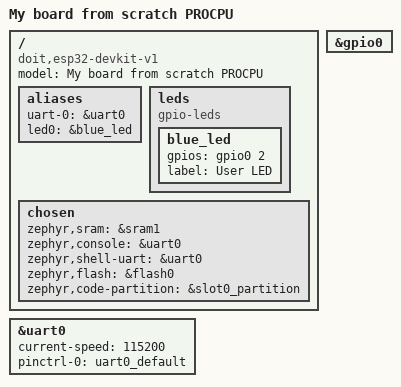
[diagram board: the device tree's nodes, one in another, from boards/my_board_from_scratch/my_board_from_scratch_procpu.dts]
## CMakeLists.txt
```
cmake_minimum_required(VERSION 3.20.0)

list (APPEND BOARD_ROOT ${CMAKE_CURRENT_SOURCE_DIR})
find_package(Zephyr REQUIRED)
project(my_zephyr_app)

target_sources(app PRIVATE src/main.cpp)
add_subdirectory(drivers/our_driver)
```

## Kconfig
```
config APP_HEARTBEAT_PERIOD_MS
	int "App Heartbeat Period (ms)"
	default 500
	range 100 2000

menuconfig LED_SUBSYSTEM
	bool "LED Subsystem"

if LED_SUBSYSTEM

# LED blink sleep time [choice]
choice
	prompt "LED blink sleep time"
	default LED_BLINK_SLEEP_1000MS

config LED_BLINK_SLEEP_250MS
	bool "0.25s (fast)"

config LED_BLINK_SLEEP_500MS
	bool "0.5s (normal)"

config LED_BLINK_SLEEP_1000MS
	bool "1s (medium)"

config LED_BLINK_SLEEP_2000MS
	bool "2s (slow)"

endchoice # LED blink sleep time

config LED_BLINK_SLEEP_TIME_MS # Use this one in the code
	int # Hidden value, no prompt
	default 250 if LED_BLINK_SLEEP_250MS	
	default 500 if LED_BLINK_SLEEP_500MS	
	default 1000 if LED_BLINK_SLEEP_1000MS	
	default 2000 if LED_BLINK_SLEEP_2000MS
	default 0


menuconfig ADVANCED_LED_SETTINGS 
	bool "Advanced LED settings"

if ADVANCED_LED_SETTINGS

config LED_BRIGHTNESS
	int "LED brightness (0-100)"
	default 100
	range 0 100

config LED_FADE_DURATION
	int "LED fade duration (ms)"
	default 500
	range 0 5000

#menu "Expert settings"
#config EXPERT_SETTINGS
#	bool "Expert settings"

# Expert settings [menu with visible if]
	# bool led debugging [config]
	# bool custom blink pattern [config]
menu "Expert settings"
visible if ADVANCED_LED_SETTINGS

config ENABLE_LED_DEBUGGING
	bool "Enable LED debugging"
	default 0

config CUSTOM_BLINK_PATTERN
	bool "Custom blink pattern"
	default 0

endmenu # Expert settings


endif # ADVANCED_LED_SETTINGS
endif # LED_SUBSYSTEM

source "Kconfig.zephyr"
rsource "drivers/our_driver/Kconfig"
```

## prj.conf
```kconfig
CONFIG_GPIO=y
CONFIG_LOG=y
CONFIG_OUR_DRIVER=y

CONFIG_SHELL=y
```

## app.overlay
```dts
/ {
	our_driver0: our_driver {
		compatible = "our,driver";
		status = "okay";
	};

	aliases {
		app-led = &blue_led;		
	};
};
```

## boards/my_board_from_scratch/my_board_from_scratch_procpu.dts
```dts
/*
 * Copyright (c) 2025 Siratul Islam
 *
 * SPDX-License-Identifier: Apache-2.0
 */
/dts-v1/;

#include <espressif/esp32/esp32_wroom_32ue_n4.dtsi>
#include "doit_esp32_devkit_v1-pinctrl.dtsi"
#include <zephyr/dt-bindings/input/input-event-codes.h>
#include <espressif/partitions_0x1000_amp.dtsi>

/ {
	model = "My board from scratch PROCPU";
	compatible = "doit,esp32-devkit-v1";

	aliases {
		uart-0 = &uart0;
		led0 = &blue_led;
	};

	leds {
		compatible = "gpio-leds";

		blue_led: blue_led {
			gpios = <&gpio0 2 GPIO_ACTIVE_HIGH>;
			label = "User LED";
		};
	};

	chosen {
		zephyr,sram = &sram1;
		zephyr,console = &uart0;
		zephyr,shell-uart = &uart0;
		zephyr,flash = &flash0;
		zephyr,code-partition = &slot0_partition;
	};
};

&uart0 {
	status = "okay";
	current-speed = <115200>;
	pinctrl-0 = <&uart0_default>;
	pinctrl-names = "default";
};


&gpio0 {
	status = "okay";
};
```

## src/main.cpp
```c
#include <zephyr/drivers/gpio.h>
#include <zephyr/kernel.h>
#include <zephyr/logging/log.h>

#include <zephyr/drivers/sensor.h> 
#include "our_driver.h" 


/* #define SLEEP_TIME_MS 1000 */

/* The devicetree node identifier for the "led0" alias. */
#define LED_NODE DT_ALIAS(led0)
#define APP_LED DT_ALIAS(app_led)

// From Module 3
//static const struct gpio_dt_spec led = GPIO_DT_SPEC_GET(LED_NODE, gpios);
// From Module 4
static const struct gpio_dt_spec led = GPIO_DT_SPEC_GET(APP_LED, gpios);

LOG_MODULE_REGISTER(main, LOG_LEVEL_INF);

namespace {
	void test(){
		const struct device* driver = DEVICE_DT_GET(DT_NODELABEL(our_driver0));
		struct sensor_value val;

		sensor_sample_fetch(driver);
		k_msleep(500);
		int ret = sensor_channel_get(driver, SENSOR_CHAN_AMBIENT_TEMP, &val);
		LOG_INF("Channel ret %d", ret);

                int count = our_driver_bump_counter(driver);
                LOG_INF("Bump counter returned %d", count);

	}
}


int main(void)
{
//    test();

/*    bool led_state = true;

    if (!gpio_is_ready_dt(&led)) return 0;

    if (gpio_pin_configure_dt(&led, GPIO_OUTPUT_ACTIVE) < 0) return 0;
*/
    while (1) {
//	test();
/*        if (gpio_pin_toggle_dt(&led) < 0) return 0;

        led_state = !led_state;
        LOG_INF("LED state: %s", led_state ? "ON" : "OFF");
*/	// From Module 3
        //k_msleep(CONFIG_LED_BLINK_SLEEP_TIME_MS);
        // From Module 4  
	k_msleep(CONFIG_APP_HEARTBEAT_PERIOD_MS);
    }
    return 0;
}
```
